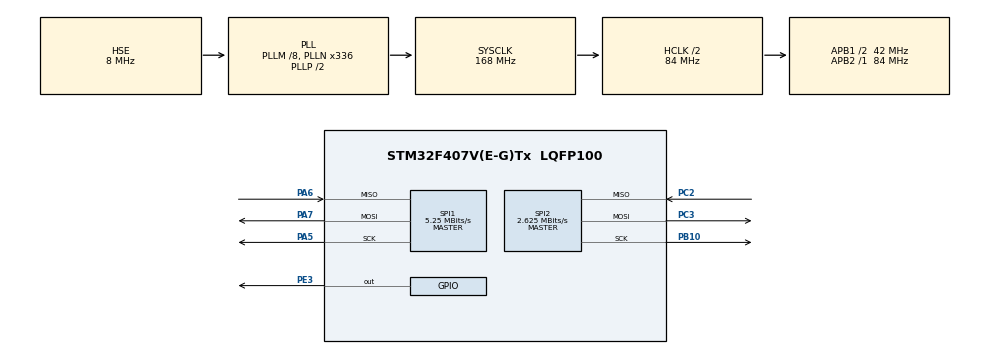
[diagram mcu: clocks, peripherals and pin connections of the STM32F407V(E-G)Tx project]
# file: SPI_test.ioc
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Mcu.Family=STM32F4
Mcu.Name=STM32F407V(E-G)Tx
Mcu.Package=LQFP100
NVIC.PriorityGroup=NVIC_PRIORITYGROUP_4
PA5.Mode=Full_Duplex_Master
PA5.Signal=SPI1_SCK
PA6.Mode=Full_Duplex_Master
PA6.Signal=SPI1_MISO
PA7.Mode=Full_Duplex_Master
PA7.Signal=SPI1_MOSI
PB10.Mode=Full_Duplex_Master
PB10.Signal=SPI2_SCK
PC2.Mode=Full_Duplex_Master
PC2.Signal=SPI2_MISO
PC3.Mode=Full_Duplex_Master
PC3.Signal=SPI2_MOSI
PE3.GPIO_ModeDefaultOutputPP=GPIO_MODE_OUTPUT_PP
PE3.GPIO_PuPd=GPIO_NOPULL
PE3.GPIO_Speed=GPIO_SPEED_FREQ_HIGH
PE3.Signal=GPIO_Output
PH0-OSC_IN.Mode=HSE-External-Oscillator
PH0-OSC_IN.Signal=RCC_OSC_IN
PH1-OSC_OUT.Mode=HSE-External-Oscillator
PH1-OSC_OUT.Signal=RCC_OSC_OUT
ProjectManager.HeapSize=0x200
ProjectManager.StackSize=0x400
ProjectManager.TargetToolchain=STM32CubeIDE
RCC.48MHZClocksFreq_Value=84000000
RCC.AHBCLKDivider=RCC_SYSCLK_DIV2
RCC.AHBFreq_Value=84000000
RCC.APB1CLKDivider=RCC_HCLK_DIV2
RCC.APB1Freq_Value=42000000
RCC.APB1TimFreq_Value=84000000
RCC.APB2Freq_Value=84000000
RCC.APB2TimFreq_Value=84000000
RCC.CortexFreq_Value=84000000
RCC.HCLKFreq_Value=84000000
RCC.HSE_VALUE=8000000
RCC.HSI_VALUE=16000000
RCC.LSE_VALUE=32768
RCC.PLLM=8
RCC.PLLN=336
RCC.PLLSourceVirtual=RCC_PLLSOURCE_HSE
RCC.SYSCLKFreq_VALUE=168000000
RCC.SYSCLKSource=RCC_SYSCLKSOURCE_PLLCLK
RCC.VCOOutputFreq_Value=336000000
SPI1.BaudRatePrescaler=SPI_BAUDRATEPRESCALER_16
SPI1.CalculateBaudRate=5.25 MBits/s
SPI1.Direction=SPI_DIRECTION_2LINES
SPI1.Mode=SPI_MODE_MASTER
SPI1.VirtualType=VM_MASTER
SPI2.BaudRatePrescaler=SPI_BAUDRATEPRESCALER_16
SPI2.CalculateBaudRate=2.625 MBits/s
SPI2.Direction=SPI_DIRECTION_2LINES
SPI2.Mode=SPI_MODE_MASTER
SPI2.VirtualType=VM_MASTER
board=custom

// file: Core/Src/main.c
/* USER CODE BEGIN Header */
/**
  ******************************************************************************
  * @file           : main.c
  * @brief          : Main program body
  ******************************************************************************
  * @attention
  *
  * Copyright (c) 2025 STMicroelectronics.
  * All rights reserved.
  *
  * This software is licensed under terms that can be found in the LICENSE file
  * in the root directory of this software component.
  * If no LICENSE file comes with this software, it is provided AS-IS.
  *
  ******************************************************************************
  */
/* USER CODE END Header */
#include "main.h"

/* USER CODE BEGIN PM */
#define Timeout 0x1000
/* USER CODE END PM */

SPI_HandleTypeDef hspi1;
SPI_HandleTypeDef hspi2;

void SystemClock_Config(void);
static void MX_GPIO_Init(void);
static void MX_SPI1_Init(void);
static void MX_SPI2_Init(void);

/* USER CODE BEGIN 0 */
void spi_cs_low()
{
	HAL_GPIO_WritePin(GPIOC, GPIO_PIN_0, GPIO_PIN_RESET);
}

void spi_cs_high()
{
	HAL_GPIO_WritePin(GPIOC, GPIO_PIN_0, GPIO_PIN_SET);
}
/* USER CODE END 0 */

int main(void)
{

  /* USER CODE BEGIN 1 */
	uint8_t addr = 0x01;
	uint8_t data = 0;
  /* USER CODE END 1 */

  /* MCU Configuration--------------------------------------------------------*/

  /* Reset of all peripherals, Initializes the Flash interface and the Systick. */
  HAL_Init();

  /* Configure the system clock */
  SystemClock_Config();

  /* Initialize all configured peripherals */
  MX_GPIO_Init();
  MX_SPI1_Init();
  MX_SPI2_Init();

  /* Infinite loop */
  while (1)
  {
	  spi_cs_low();

	    HAL_SPI_Transmit(&hspi2, &addr, 1, Timeout);
	  //  HAL_Delay(100);

	    spi_cs_high();
	    HAL_Delay(100);
  }
}

void SystemClock_Config(void)
{
  RCC_OscInitTypeDef RCC_OscInitStruct = {0};
  RCC_ClkInitTypeDef RCC_ClkInitStruct = {0};

  /** Configure the main internal regulator output voltage
  */
  __HAL_RCC_PWR_CLK_ENABLE();
  __HAL_PWR_VOLTAGESCALING_CONFIG(PWR_REGULATOR_VOLTAGE_SCALE1);

  /** Initializes the RCC Oscillators according to the specified parameters
  * in the RCC_OscInitTypeDef structure.
  */
  RCC_OscInitStruct.OscillatorType = RCC_OSCILLATORTYPE_HSE;
  RCC_OscInitStruct.HSEState = RCC_HSE_ON;
  RCC_OscInitStruct.PLL.PLLState = RCC_PLL_ON;
  RCC_OscInitStruct.PLL.PLLSource = RCC_PLLSOURCE_HSE;
  RCC_OscInitStruct.PLL.PLLM = 8;
  RCC_OscInitStruct.PLL.PLLN = 336;
  RCC_OscInitStruct.PLL.PLLP = RCC_PLLP_DIV2;
  RCC_OscInitStruct.PLL.PLLQ = 4;
  if (HAL_RCC_OscConfig(&RCC_OscInitStruct) != HAL_OK)
  {
    Error_Handler();
  }

  /** Initializes the CPU, AHB and APB buses clocks
  */
  RCC_ClkInitStruct.ClockType = RCC_CLOCKTYPE_HCLK|RCC_CLOCKTYPE_SYSCLK
                              |RCC_CLOCKTYPE_PCLK1|RCC_CLOCKTYPE_PCLK2;
  RCC_ClkInitStruct.SYSCLKSource = RCC_SYSCLKSOURCE_PLLCLK;
  RCC_ClkInitStruct.AHBCLKDivider = RCC_SYSCLK_DIV2;
  RCC_ClkInitStruct.APB1CLKDivider = RCC_HCLK_DIV2;
  RCC_ClkInitStruct.APB2CLKDivider = RCC_HCLK_DIV1;

  if (HAL_RCC_ClockConfig(&RCC_ClkInitStruct, FLASH_LATENCY_2) != HAL_OK)
  {
    Error_Handler();
  }
}

static void MX_SPI1_Init(void)
{

  /* SPI1 parameter configuration*/
  hspi1.Instance = SPI1;
  hspi1.Init.Mode = SPI_MODE_MASTER;
  hspi1.Init.Direction = SPI_DIRECTION_2LINES;
  hspi1.Init.DataSize = SPI_DATASIZE_8BIT;
  hspi1.Init.CLKPolarity = SPI_POLARITY_LOW;
  hspi1.Init.CLKPhase = SPI_PHASE_1EDGE;
  hspi1.Init.NSS = SPI_NSS_SOFT;
  hspi1.Init.BaudRatePrescaler = SPI_BAUDRATEPRESCALER_16;
  hspi1.Init.FirstBit = SPI_FIRSTBIT_MSB;
  hspi1.Init.TIMode = SPI_TIMODE_DISABLE;
  hspi1.Init.CRCCalculation = SPI_CRCCALCULATION_DISABLE;
  hspi1.Init.CRCPolynomial = 10;
  if (HAL_SPI_Init(&hspi1) != HAL_OK)
  {
    Error_Handler();
  }

}

static void MX_SPI2_Init(void)
{

  /* SPI2 parameter configuration*/
  hspi2.Instance = SPI2;
  hspi2.Init.Mode = SPI_MODE_MASTER;
  hspi2.Init.Direction = SPI_DIRECTION_2LINES;
  hspi2.Init.DataSize = SPI_DATASIZE_8BIT;
  hspi2.Init.CLKPolarity = SPI_POLARITY_LOW;
  hspi2.Init.CLKPhase = SPI_PHASE_1EDGE;
  hspi2.Init.NSS = SPI_NSS_SOFT;
  hspi2.Init.BaudRatePrescaler = SPI_BAUDRATEPRESCALER_16;
  hspi2.Init.FirstBit = SPI_FIRSTBIT_MSB;
  hspi2.Init.TIMode = SPI_TIMODE_DISABLE;
  hspi2.Init.CRCCalculation = SPI_CRCCALCULATION_DISABLE;
  hspi2.Init.CRCPolynomial = 10;
  if (HAL_SPI_Init(&hspi2) != HAL_OK)
  {
    Error_Handler();
  }

}

static void MX_GPIO_Init(void)
{
  GPIO_InitTypeDef GPIO_InitStruct = {0};

  /* GPIO Ports Clock Enable */
  __HAL_RCC_GPIOE_CLK_ENABLE();
  __HAL_RCC_GPIOH_CLK_ENABLE();
  __HAL_RCC_GPIOC_CLK_ENABLE();
  __HAL_RCC_GPIOA_CLK_ENABLE();
  __HAL_RCC_GPIOB_CLK_ENABLE();

  /*Configure GPIO pin Output Level */
  HAL_GPIO_WritePin(GPIOE, GPIO_PIN_0, GPIO_PIN_RESET);

  /*Configure GPIO pin : PE3 */
  GPIO_InitStruct.Pin = GPIO_PIN_0;
  GPIO_InitStruct.Mode = GPIO_MODE_OUTPUT_PP;
  GPIO_InitStruct.Pull = GPIO_NOPULL;
  GPIO_InitStruct.Speed = GPIO_SPEED_FREQ_HIGH;
  HAL_GPIO_Init(GPIOC, &GPIO_InitStruct);

  /* USER CODE BEGIN MX_GPIO_Init_2 */
  spi_cs_high();
  /* USER CODE END MX_GPIO_Init_2 */
}

void Error_Handler(void)
{
  __disable_irq();
  while (1)
  {
  }
}
